AUTOSAR XML (schema 00051)
package /Components
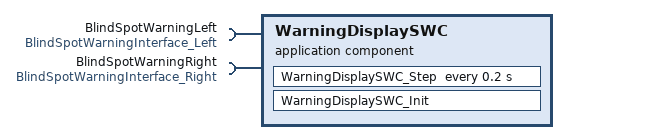
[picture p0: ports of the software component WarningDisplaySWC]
  application sw component type WarningDisplaySWC
    require port BlindSpotWarningLeft: nonqueued-receiver-com-spec{data-element=detected, init-value=0}, required-interface=BlindSpotWarningInterface_Left
    require port BlindSpotWarningRight: nonqueued-receiver-com-spec{data-element=detected, init-value=0}, required-interface=BlindSpotWarningInterface_Right
    behavior WarningDisplaySWC_IB: handle-termination-and-restart=NO-SUPPORT
      timing event Event: start-on-event=WarningDisplaySWC_Step, period=0.2
      runnable WarningDisplaySWC_Init
      runnable WarningDisplaySWC_Step
